# ECC_AGGR4_ECC_AGGR register map
Vendor: Texas Instruments
Registers are 32-bit, access not given, reset 0x0 unless marked. A register's access mark holds for its fields unless they carry their own. Offsets are as the file gives them; [hi:lo] are bit positions.

## ECC_AGGR4_ECC_AGGR (part 6 of 6)
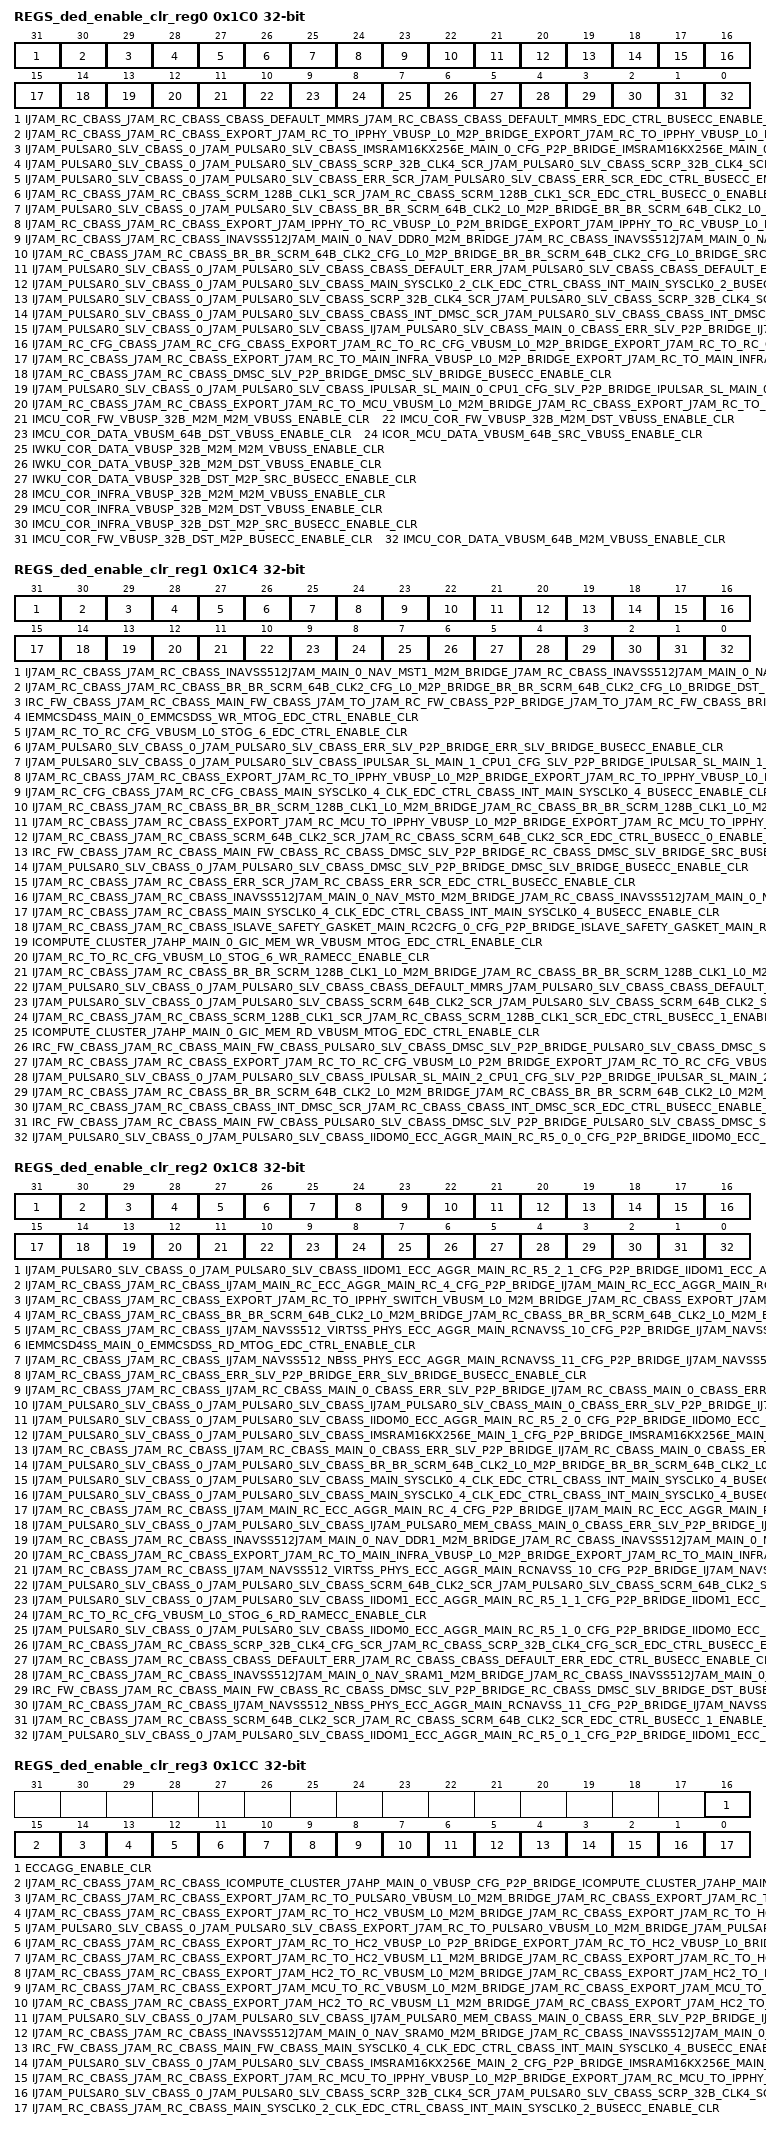
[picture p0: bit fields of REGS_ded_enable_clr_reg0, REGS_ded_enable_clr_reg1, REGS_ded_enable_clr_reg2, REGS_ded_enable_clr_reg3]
0x1C0 REGS_ded_enable_clr_reg0 — Interrupt Enable Clear Register 0
  [31] IJ7AM_RC_CBASS_J7AM_RC_CBASS_CBASS_DEFAULT_MMRS_J7AM_RC_CBASS_CBASS_DEFAULT_MMRS_EDC_CTRL_BUSECC_ENABLE_CLR — Interrupt Enable Clear Register for Ij7am_rc_cbass_j7am_rc_cbass_cbass_default_mmrs_j7am_rc_cbass_cbass_default_mmrs_edc_ctrl_busecc_pend (access R/W1TC)
  [30] IJ7AM_RC_CBASS_J7AM_RC_CBASS_EXPORT_J7AM_RC_TO_IPPHY_VBUSP_L0_M2P_BRIDGE_EXPORT_J7AM_RC_TO_IPPHY_VBUSP_L0_BRIDGE_DST_BUSECC_ENABLE_CLR — Interrupt Enable Clear Register for Ij7am_rc_cbass_j7am_rc_cbass_export_j7am_rc_to_ipphy_vbusp_l0_m2p_bridge_export_j7am_rc_to_ipphy_vbusp_l0_bridge_dst_busecc_pend (access R/W1TC)
  [29] IJ7AM_PULSAR0_SLV_CBASS_0_J7AM_PULSAR0_SLV_CBASS_IMSRAM16KX256E_MAIN_0_CFG_P2P_BRIDGE_IMSRAM16KX256E_MAIN_0_CFG_BRIDGE_BUSECC_ENABLE_CLR — Interrupt Enable Clear Register for Ij7am_pulsar0_slv_cbass_0_j7am_pulsar0_slv_cbass_Imsram16kx256e_main_0_cfg_p2p_bridge_Imsram16kx256e_main_0_cfg_bridge_busecc_pend (access R/W1TC)
  [28] IJ7AM_PULSAR0_SLV_CBASS_0_J7AM_PULSAR0_SLV_CBASS_SCRP_32B_CLK4_SCR_J7AM_PULSAR0_SLV_CBASS_SCRP_32B_CLK4_SCR_EDC_CTRL_BUSECC_2_ENABLE_CLR — Interrupt Enable Clear Register for Ij7am_pulsar0_slv_cbass_0_j7am_pulsar0_slv_cbass_scrp_32b_clk4_scr_j7am_pulsar0_slv_cbass_scrp_32b_clk4_scr_edc_ctrl_busecc_2_pend (access R/W1TC)
  [27] IJ7AM_PULSAR0_SLV_CBASS_0_J7AM_PULSAR0_SLV_CBASS_ERR_SCR_J7AM_PULSAR0_SLV_CBASS_ERR_SCR_EDC_CTRL_BUSECC_ENABLE_CLR — Interrupt Enable Clear Register for Ij7am_pulsar0_slv_cbass_0_j7am_pulsar0_slv_cbass_err_scr_j7am_pulsar0_slv_cbass_err_scr_edc_ctrl_busecc_pend (access R/W1TC)
  [26] IJ7AM_RC_CBASS_J7AM_RC_CBASS_SCRM_128B_CLK1_SCR_J7AM_RC_CBASS_SCRM_128B_CLK1_SCR_EDC_CTRL_BUSECC_0_ENABLE_CLR — Interrupt Enable Clear Register for Ij7am_rc_cbass_j7am_rc_cbass_scrm_128b_clk1_scr_j7am_rc_cbass_scrm_128b_clk1_scr_edc_ctrl_busecc_0_pend (access R/W1TC)
  [25] IJ7AM_PULSAR0_SLV_CBASS_0_J7AM_PULSAR0_SLV_CBASS_BR_BR_SCRM_64B_CLK2_L0_M2P_BRIDGE_BR_BR_SCRM_64B_CLK2_L0_BRIDGE_DST_BUSECC_ENABLE_CLR — Interrupt Enable Clear Register for Ij7am_pulsar0_slv_cbass_0_j7am_pulsar0_slv_cbass_br_br_scrm_64b_clk2_l0_m2p_bridge_br_br_scrm_64b_clk2_l0_bridge_dst_busecc_pend (access R/W1TC)
  [24] IJ7AM_RC_CBASS_J7AM_RC_CBASS_EXPORT_J7AM_IPPHY_TO_RC_VBUSP_L0_P2M_BRIDGE_EXPORT_J7AM_IPPHY_TO_RC_VBUSP_L0_BRIDGE_BUSECC_ENABLE_CLR — Interrupt Enable Clear Register for Ij7am_rc_cbass_j7am_rc_cbass_export_j7am_ipphy_to_rc_vbusp_l0_p2m_bridge_export_j7am_ipphy_to_rc_vbusp_l0_bridge_busecc_pend (access R/W1TC)
  [23] IJ7AM_RC_CBASS_J7AM_RC_CBASS_INAVSS512J7AM_MAIN_0_NAV_DDR0_M2M_BRIDGE_J7AM_RC_CBASS_INAVSS512J7AM_MAIN_0_NAV_DDR0_M2M_BRIDGE_SRC_EDC_CTRL_BUSECC_ENABLE_CLR — Interrupt Enable Clear Register for Ij7am_rc_cbass_j7am_rc_cbass_Inavss512j7am_main_0_nav_ddr0_m2m_bridge_j7am_rc_cbass_Inavss512j7am_main_0_nav_ddr0_m2m_bridge_src_edc_ctrl_busecc_pend (access R/W1TC)
  [22] IJ7AM_RC_CBASS_J7AM_RC_CBASS_BR_BR_SCRM_64B_CLK2_CFG_L0_M2P_BRIDGE_BR_BR_SCRM_64B_CLK2_CFG_L0_BRIDGE_SRC_BUSECC_ENABLE_CLR — Interrupt Enable Clear Register for Ij7am_rc_cbass_j7am_rc_cbass_br_br_scrm_64b_clk2_cfg_l0_m2p_bridge_br_br_scrm_64b_clk2_cfg_l0_bridge_src_busecc_pend (access R/W1TC)
  [21] IJ7AM_PULSAR0_SLV_CBASS_0_J7AM_PULSAR0_SLV_CBASS_CBASS_DEFAULT_ERR_J7AM_PULSAR0_SLV_CBASS_CBASS_DEFAULT_ERR_EDC_CTRL_BUSECC_ENABLE_CLR — Interrupt Enable Clear Register for Ij7am_pulsar0_slv_cbass_0_j7am_pulsar0_slv_cbass_cbass_default_err_j7am_pulsar0_slv_cbass_cbass_default_err_edc_ctrl_busecc_pend (access R/W1TC)
  [20] IJ7AM_PULSAR0_SLV_CBASS_0_J7AM_PULSAR0_SLV_CBASS_MAIN_SYSCLK0_2_CLK_EDC_CTRL_CBASS_INT_MAIN_SYSCLK0_2_BUSECC_ENABLE_CLR — Interrupt Enable Clear Register for Ij7am_pulsar0_slv_cbass_0_j7am_pulsar0_slv_cbass_main_SYSCLK0_2_clk_edc_ctrl_cbass_int_main_SYSCLK0_2_busecc_pend (access R/W1TC)
  [19] IJ7AM_PULSAR0_SLV_CBASS_0_J7AM_PULSAR0_SLV_CBASS_SCRP_32B_CLK4_SCR_J7AM_PULSAR0_SLV_CBASS_SCRP_32B_CLK4_SCR_EDC_CTRL_BUSECC_1_ENABLE_CLR — Interrupt Enable Clear Register for Ij7am_pulsar0_slv_cbass_0_j7am_pulsar0_slv_cbass_scrp_32b_clk4_scr_j7am_pulsar0_slv_cbass_scrp_32b_clk4_scr_edc_ctrl_busecc_1_pend (access R/W1TC)
  [18] IJ7AM_PULSAR0_SLV_CBASS_0_J7AM_PULSAR0_SLV_CBASS_CBASS_INT_DMSC_SCR_J7AM_PULSAR0_SLV_CBASS_CBASS_INT_DMSC_SCR_EDC_CTRL_BUSECC_ENABLE_CLR — Interrupt Enable Clear Register for Ij7am_pulsar0_slv_cbass_0_j7am_pulsar0_slv_cbass_cbass_int_dmsc_scr_j7am_pulsar0_slv_cbass_cbass_int_dmsc_scr_edc_ctrl_busecc_pend (access R/W1TC)
  [17] IJ7AM_PULSAR0_SLV_CBASS_0_J7AM_PULSAR0_SLV_CBASS_IJ7AM_PULSAR0_SLV_CBASS_MAIN_0_CBASS_ERR_SLV_P2P_BRIDGE_IJ7AM_PULSAR0_SLV_CBASS_MAIN_0_CBASS_ERR_SLV_BRIDGE_SRC_BUSECC_ENABLE_CLR — Interrupt Enable Clear Register for Ij7am_pulsar0_slv_cbass_0_j7am_pulsar0_slv_cbass_Ij7am_pulsar0_slv_cbass_main_0_cbass_err_slv_p2p_bridge_Ij7am_pulsar0_slv_cbass_main_0_cbass_err_slv_bridge_src_busecc_pend (access R/W1TC)
  [16] IJ7AM_RC_CFG_CBASS_J7AM_RC_CFG_CBASS_EXPORT_J7AM_RC_TO_RC_CFG_VBUSM_L0_M2P_BRIDGE_EXPORT_J7AM_RC_TO_RC_CFG_VBUSM_L0_BRIDGE_BUSECC_ENABLE_CLR — Interrupt Enable Clear Register for Ij7am_rc_cfg_cbass_j7am_rc_cfg_cbass_export_j7am_rc_to_rc_cfg_vbusm_l0_m2p_bridge_export_j7am_rc_to_rc_cfg_vbusm_l0_bridge_busecc_pend (access R/W1TC)
  [15] IJ7AM_RC_CBASS_J7AM_RC_CBASS_EXPORT_J7AM_RC_TO_MAIN_INFRA_VBUSP_L0_M2P_BRIDGE_EXPORT_J7AM_RC_TO_MAIN_INFRA_VBUSP_L0_BRIDGE_SRC_BUSECC_ENABLE_CLR — Interrupt Enable Clear Register for Ij7am_rc_cbass_j7am_rc_cbass_export_j7am_rc_to_main_infra_vbusp_l0_m2p_bridge_export_j7am_rc_to_main_infra_vbusp_l0_bridge_src_busecc_pend (access R/W1TC)
  [14] IJ7AM_RC_CBASS_J7AM_RC_CBASS_DMSC_SLV_P2P_BRIDGE_DMSC_SLV_BRIDGE_BUSECC_ENABLE_CLR — Interrupt Enable Clear Register for Ij7am_rc_cbass_j7am_rc_cbass_dmsc_slv_p2p_bridge_dmsc_slv_bridge_busecc_pend (access R/W1TC)
  [13] IJ7AM_PULSAR0_SLV_CBASS_0_J7AM_PULSAR0_SLV_CBASS_IPULSAR_SL_MAIN_0_CPU1_CFG_SLV_P2P_BRIDGE_IPULSAR_SL_MAIN_0_CPU1_CFG_SLV_BRIDGE_BUSECC_ENABLE_CLR — Interrupt Enable Clear Register for Ij7am_pulsar0_slv_cbass_0_j7am_pulsar0_slv_cbass_Ipulsar_sl_main_0_cpu1_cfg_slv_p2p_bridge_Ipulsar_sl_main_0_cpu1_cfg_slv_bridge_busecc_pend (access R/W1TC)
  [12] IJ7AM_RC_CBASS_J7AM_RC_CBASS_EXPORT_J7AM_RC_TO_MCU_VBUSM_L0_M2M_BRIDGE_J7AM_RC_CBASS_EXPORT_J7AM_RC_TO_MCU_VBUSM_L0_M2M_BRIDGE_SRC_EDC_CTRL_BUSECC_ENABLE_CLR — Interrupt Enable Clear Register for Ij7am_rc_cbass_j7am_rc_cbass_export_j7am_rc_to_mcu_vbusm_l0_m2m_bridge_j7am_rc_cbass_export_j7am_rc_to_mcu_vbusm_l0_m2m_bridge_src_edc_ctrl_busecc_pend (access R/W1TC)
  [11] IMCU_COR_FW_VBUSP_32B_M2M_M2M_VBUSS_ENABLE_CLR — Interrupt Enable Clear Register for Imcu_cor_fw_vbusp_32b_m2m_m2m_vbuss_pend (access R/W1TC)
  [10] IMCU_COR_FW_VBUSP_32B_M2M_DST_VBUSS_ENABLE_CLR — Interrupt Enable Clear Register for Imcu_cor_fw_vbusp_32b_m2m_dst_vbuss_pend (access R/W1TC)
  [9] IMCU_COR_DATA_VBUSM_64B_DST_VBUSS_ENABLE_CLR — Interrupt Enable Clear Register for Imcu_cor_data_vbusm_64b_dst_vbuss_pend (access R/W1TC)
  [8] ICOR_MCU_DATA_VBUSM_64B_SRC_VBUSS_ENABLE_CLR — Interrupt Enable Clear Register for Icor_mcu_data_vbusm_64b_src_vbuss_pend (access R/W1TC)
  [7] IWKU_COR_DATA_VBUSP_32B_M2M_M2M_VBUSS_ENABLE_CLR — Interrupt Enable Clear Register for Iwku_cor_data_vbusp_32b_m2m_m2m_vbuss_pend (access R/W1TC)
  [6] IWKU_COR_DATA_VBUSP_32B_M2M_DST_VBUSS_ENABLE_CLR — Interrupt Enable Clear Register for Iwku_cor_data_vbusp_32b_m2m_dst_vbuss_pend (access R/W1TC)
  [5] IWKU_COR_DATA_VBUSP_32B_DST_M2P_SRC_BUSECC_ENABLE_CLR — Interrupt Enable Clear Register for Iwku_cor_data_vbusp_32b_dst_m2p_src_busecc_pend (access R/W1TC)
  [4] IMCU_COR_INFRA_VBUSP_32B_M2M_M2M_VBUSS_ENABLE_CLR — Interrupt Enable Clear Register for Imcu_cor_infra_vbusp_32b_m2m_m2m_vbuss_pend (access R/W1TC)
  [3] IMCU_COR_INFRA_VBUSP_32B_M2M_DST_VBUSS_ENABLE_CLR — Interrupt Enable Clear Register for Imcu_cor_infra_vbusp_32b_m2m_dst_vbuss_pend (access R/W1TC)
  [2] IMCU_COR_INFRA_VBUSP_32B_DST_M2P_SRC_BUSECC_ENABLE_CLR — Interrupt Enable Clear Register for Imcu_cor_infra_vbusp_32b_dst_m2p_src_busecc_pend (access R/W1TC)
  [1] IMCU_COR_FW_VBUSP_32B_DST_M2P_BUSECC_ENABLE_CLR — Interrupt Enable Clear Register for Imcu_cor_fw_vbusp_32b_dst_m2p_busecc_pend (access R/W1TC)
  [0] IMCU_COR_DATA_VBUSM_64B_M2M_VBUSS_ENABLE_CLR — Interrupt Enable Clear Register for Imcu_cor_data_vbusm_64b_m2m_vbuss_pend (access R/W1TC)
0x1C4 REGS_ded_enable_clr_reg1 — Interrupt Enable Clear Register 1
  [31] IJ7AM_RC_CBASS_J7AM_RC_CBASS_INAVSS512J7AM_MAIN_0_NAV_MST1_M2M_BRIDGE_J7AM_RC_CBASS_INAVSS512J7AM_MAIN_0_NAV_MST1_M2M_BRIDGE_SRC_EDC_CTRL_BUSECC_ENABLE_CLR — Interrupt Enable Clear Register for Ij7am_rc_cbass_j7am_rc_cbass_Inavss512j7am_main_0_nav_mst1_m2m_bridge_j7am_rc_cbass_Inavss512j7am_main_0_nav_mst1_m2m_bridge_src_edc_ctrl_busecc_pend (access R/W1TC)
  [30] IJ7AM_RC_CBASS_J7AM_RC_CBASS_BR_BR_SCRM_64B_CLK2_CFG_L0_M2P_BRIDGE_BR_BR_SCRM_64B_CLK2_CFG_L0_BRIDGE_DST_BUSECC_ENABLE_CLR — Interrupt Enable Clear Register for Ij7am_rc_cbass_j7am_rc_cbass_br_br_scrm_64b_clk2_cfg_l0_m2p_bridge_br_br_scrm_64b_clk2_cfg_l0_bridge_dst_busecc_pend (access R/W1TC)
  [29] IRC_FW_CBASS_J7AM_RC_CBASS_MAIN_FW_CBASS_J7AM_TO_J7AM_RC_FW_CBASS_P2P_BRIDGE_J7AM_TO_J7AM_RC_FW_CBASS_BRIDGE_BUSECC_ENABLE_CLR — Interrupt Enable Clear Register for Irc_fw_cbass_j7am_rc_cbass_main_fw_cbass_j7am_to_j7am_rc_fw_cbass_p2p_bridge_j7am_to_j7am_rc_fw_cbass_bridge_busecc_pend (access R/W1TC)
  [28] IEMMCSD4SS_MAIN_0_EMMCSDSS_WR_MTOG_EDC_CTRL_ENABLE_CLR — Interrupt Enable Clear Register for Iemmcsd4ss_main_0_emmcsdss_wr_mtog_edc_ctrl_pend (access R/W1TC)
  [27] IJ7AM_RC_TO_RC_CFG_VBUSM_L0_STOG_6_EDC_CTRL_ENABLE_CLR — Interrupt Enable Clear Register for Ij7am_rc_to_rc_cfg_vbusm_l0_stog_6_edc_ctrl_pend (access R/W1TC)
  [26] IJ7AM_PULSAR0_SLV_CBASS_0_J7AM_PULSAR0_SLV_CBASS_ERR_SLV_P2P_BRIDGE_ERR_SLV_BRIDGE_BUSECC_ENABLE_CLR — Interrupt Enable Clear Register for Ij7am_pulsar0_slv_cbass_0_j7am_pulsar0_slv_cbass_err_slv_p2p_bridge_err_slv_bridge_busecc_pend (access R/W1TC)
  [25] IJ7AM_PULSAR0_SLV_CBASS_0_J7AM_PULSAR0_SLV_CBASS_IPULSAR_SL_MAIN_1_CPU1_CFG_SLV_P2P_BRIDGE_IPULSAR_SL_MAIN_1_CPU1_CFG_SLV_BRIDGE_BUSECC_ENABLE_CLR — Interrupt Enable Clear Register for Ij7am_pulsar0_slv_cbass_0_j7am_pulsar0_slv_cbass_Ipulsar_sl_main_1_cpu1_cfg_slv_p2p_bridge_Ipulsar_sl_main_1_cpu1_cfg_slv_bridge_busecc_pend (access R/W1TC)
  [24] IJ7AM_RC_CBASS_J7AM_RC_CBASS_EXPORT_J7AM_RC_TO_IPPHY_VBUSP_L0_M2P_BRIDGE_EXPORT_J7AM_RC_TO_IPPHY_VBUSP_L0_BRIDGE_SRC_BUSECC_ENABLE_CLR — Interrupt Enable Clear Register for Ij7am_rc_cbass_j7am_rc_cbass_export_j7am_rc_to_ipphy_vbusp_l0_m2p_bridge_export_j7am_rc_to_ipphy_vbusp_l0_bridge_src_busecc_pend (access R/W1TC)
  [23] IJ7AM_RC_CFG_CBASS_J7AM_RC_CFG_CBASS_MAIN_SYSCLK0_4_CLK_EDC_CTRL_CBASS_INT_MAIN_SYSCLK0_4_BUSECC_ENABLE_CLR — Interrupt Enable Clear Register for Ij7am_rc_cfg_cbass_j7am_rc_cfg_cbass_main_SYSCLK0_4_clk_edc_ctrl_cbass_int_main_SYSCLK0_4_busecc_pend (access R/W1TC)
  [22] IJ7AM_RC_CBASS_J7AM_RC_CBASS_BR_BR_SCRM_128B_CLK1_L0_M2M_BRIDGE_J7AM_RC_CBASS_BR_BR_SCRM_128B_CLK1_L0_M2M_BRIDGE_SRC_EDC_CTRL_BUSECC_ENABLE_CLR — Interrupt Enable Clear Register for Ij7am_rc_cbass_j7am_rc_cbass_br_br_scrm_128b_clk1_l0_m2m_bridge_j7am_rc_cbass_br_br_scrm_128b_clk1_l0_m2m_bridge_src_edc_ctrl_busecc_pend (access R/W1TC)
  [21] IJ7AM_RC_CBASS_J7AM_RC_CBASS_EXPORT_J7AM_RC_MCU_TO_IPPHY_VBUSP_L0_M2P_BRIDGE_EXPORT_J7AM_RC_MCU_TO_IPPHY_VBUSP_L0_BRIDGE_DST_BUSECC_ENABLE_CLR — Interrupt Enable Clear Register for Ij7am_rc_cbass_j7am_rc_cbass_export_j7am_rc_mcu_to_ipphy_vbusp_l0_m2p_bridge_export_j7am_rc_mcu_to_ipphy_vbusp_l0_bridge_dst_busecc_pend (access R/W1TC)
  [20] IJ7AM_RC_CBASS_J7AM_RC_CBASS_SCRM_64B_CLK2_SCR_J7AM_RC_CBASS_SCRM_64B_CLK2_SCR_EDC_CTRL_BUSECC_0_ENABLE_CLR — Interrupt Enable Clear Register for Ij7am_rc_cbass_j7am_rc_cbass_scrm_64b_clk2_scr_j7am_rc_cbass_scrm_64b_clk2_scr_edc_ctrl_busecc_0_pend (access R/W1TC)
  [19] IRC_FW_CBASS_J7AM_RC_CBASS_MAIN_FW_CBASS_RC_CBASS_DMSC_SLV_P2P_BRIDGE_RC_CBASS_DMSC_SLV_BRIDGE_SRC_BUSECC_ENABLE_CLR — Interrupt Enable Clear Register for Irc_fw_cbass_j7am_rc_cbass_main_fw_cbass_rc_cbass_dmsc_slv_p2p_bridge_rc_cbass_dmsc_slv_bridge_src_busecc_pend (access R/W1TC)
  [18] IJ7AM_PULSAR0_SLV_CBASS_0_J7AM_PULSAR0_SLV_CBASS_DMSC_SLV_P2P_BRIDGE_DMSC_SLV_BRIDGE_BUSECC_ENABLE_CLR — Interrupt Enable Clear Register for Ij7am_pulsar0_slv_cbass_0_j7am_pulsar0_slv_cbass_dmsc_slv_p2p_bridge_dmsc_slv_bridge_busecc_pend (access R/W1TC)
  [17] IJ7AM_RC_CBASS_J7AM_RC_CBASS_ERR_SCR_J7AM_RC_CBASS_ERR_SCR_EDC_CTRL_BUSECC_ENABLE_CLR — Interrupt Enable Clear Register for Ij7am_rc_cbass_j7am_rc_cbass_err_scr_j7am_rc_cbass_err_scr_edc_ctrl_busecc_pend (access R/W1TC)
  [16] IJ7AM_RC_CBASS_J7AM_RC_CBASS_INAVSS512J7AM_MAIN_0_NAV_MST0_M2M_BRIDGE_J7AM_RC_CBASS_INAVSS512J7AM_MAIN_0_NAV_MST0_M2M_BRIDGE_SRC_EDC_CTRL_BUSECC_ENABLE_CLR — Interrupt Enable Clear Register for Ij7am_rc_cbass_j7am_rc_cbass_Inavss512j7am_main_0_nav_mst0_m2m_bridge_j7am_rc_cbass_Inavss512j7am_main_0_nav_mst0_m2m_bridge_src_edc_ctrl_busecc_pend (access R/W1TC)
  [15] IJ7AM_RC_CBASS_J7AM_RC_CBASS_MAIN_SYSCLK0_4_CLK_EDC_CTRL_CBASS_INT_MAIN_SYSCLK0_4_BUSECC_ENABLE_CLR — Interrupt Enable Clear Register for Ij7am_rc_cbass_j7am_rc_cbass_main_SYSCLK0_4_clk_edc_ctrl_cbass_int_main_SYSCLK0_4_busecc_pend (access R/W1TC)
  [14] IJ7AM_RC_CBASS_J7AM_RC_CBASS_ISLAVE_SAFETY_GASKET_MAIN_RC2CFG_0_CFG_P2P_BRIDGE_ISLAVE_SAFETY_GASKET_MAIN_RC2CFG_0_CFG_BRIDGE_BUSECC_ENABLE_CLR — Interrupt Enable Clear Register for Ij7am_rc_cbass_j7am_rc_cbass_Islave_safety_gasket_main_rc2cfg_0_cfg_p2p_bridge_Islave_safety_gasket_main_rc2cfg_0_cfg_bridge_busecc_pend (access R/W1TC)
  [13] ICOMPUTE_CLUSTER_J7AHP_MAIN_0_GIC_MEM_WR_VBUSM_MTOG_EDC_CTRL_ENABLE_CLR — Interrupt Enable Clear Register for Icompute_cluster_j7ahp_main_0_gic_mem_wr_vbusm_mtog_edc_ctrl_pend (access R/W1TC)
  [12] IJ7AM_RC_TO_RC_CFG_VBUSM_L0_STOG_6_WR_RAMECC_ENABLE_CLR — Interrupt Enable Clear Register for Ij7am_rc_to_rc_cfg_vbusm_l0_stog_6_wr_ramecc_pend (access R/W1TC)
  [11] IJ7AM_RC_CBASS_J7AM_RC_CBASS_BR_BR_SCRM_128B_CLK1_L0_M2M_BRIDGE_J7AM_RC_CBASS_BR_BR_SCRM_128B_CLK1_L0_M2M_BRIDGE_DST_EDC_CTRL_BUSECC_ENABLE_CLR — Interrupt Enable Clear Register for Ij7am_rc_cbass_j7am_rc_cbass_br_br_scrm_128b_clk1_l0_m2m_bridge_j7am_rc_cbass_br_br_scrm_128b_clk1_l0_m2m_bridge_dst_edc_ctrl_busecc_pend (access R/W1TC)
  [10] IJ7AM_PULSAR0_SLV_CBASS_0_J7AM_PULSAR0_SLV_CBASS_CBASS_DEFAULT_MMRS_J7AM_PULSAR0_SLV_CBASS_CBASS_DEFAULT_MMRS_EDC_CTRL_BUSECC_ENABLE_CLR — Interrupt Enable Clear Register for Ij7am_pulsar0_slv_cbass_0_j7am_pulsar0_slv_cbass_cbass_default_mmrs_j7am_pulsar0_slv_cbass_cbass_default_mmrs_edc_ctrl_busecc_pend (access R/W1TC)
  [9] IJ7AM_PULSAR0_SLV_CBASS_0_J7AM_PULSAR0_SLV_CBASS_SCRM_64B_CLK2_SCR_J7AM_PULSAR0_SLV_CBASS_SCRM_64B_CLK2_SCR_EDC_CTRL_BUSECC_1_ENABLE_CLR — Interrupt Enable Clear Register for Ij7am_pulsar0_slv_cbass_0_j7am_pulsar0_slv_cbass_scrm_64b_clk2_scr_j7am_pulsar0_slv_cbass_scrm_64b_clk2_scr_edc_ctrl_busecc_1_pend (access R/W1TC)
  [8] IJ7AM_RC_CBASS_J7AM_RC_CBASS_SCRM_128B_CLK1_SCR_J7AM_RC_CBASS_SCRM_128B_CLK1_SCR_EDC_CTRL_BUSECC_1_ENABLE_CLR — Interrupt Enable Clear Register for Ij7am_rc_cbass_j7am_rc_cbass_scrm_128b_clk1_scr_j7am_rc_cbass_scrm_128b_clk1_scr_edc_ctrl_busecc_1_pend (access R/W1TC)
  [7] ICOMPUTE_CLUSTER_J7AHP_MAIN_0_GIC_MEM_RD_VBUSM_MTOG_EDC_CTRL_ENABLE_CLR — Interrupt Enable Clear Register for Icompute_cluster_j7ahp_main_0_gic_mem_rd_vbusm_mtog_edc_ctrl_pend (access R/W1TC)
  [6] IRC_FW_CBASS_J7AM_RC_CBASS_MAIN_FW_CBASS_PULSAR0_SLV_CBASS_DMSC_SLV_P2P_BRIDGE_PULSAR0_SLV_CBASS_DMSC_SLV_BRIDGE_DST_BUSECC_ENABLE_CLR — Interrupt Enable Clear Register for Irc_fw_cbass_j7am_rc_cbass_main_fw_cbass_pulsar0_slv_cbass_dmsc_slv_p2p_bridge_pulsar0_slv_cbass_dmsc_slv_bridge_dst_busecc_pend (access R/W1TC)
  [5] IJ7AM_RC_CBASS_J7AM_RC_CBASS_EXPORT_J7AM_RC_TO_RC_CFG_VBUSM_L0_P2M_BRIDGE_EXPORT_J7AM_RC_TO_RC_CFG_VBUSM_L0_BRIDGE_BUSECC_ENABLE_CLR — Interrupt Enable Clear Register for Ij7am_rc_cbass_j7am_rc_cbass_export_j7am_rc_to_rc_cfg_vbusm_l0_p2m_bridge_export_j7am_rc_to_rc_cfg_vbusm_l0_bridge_busecc_pend (access R/W1TC)
  [4] IJ7AM_PULSAR0_SLV_CBASS_0_J7AM_PULSAR0_SLV_CBASS_IPULSAR_SL_MAIN_2_CPU1_CFG_SLV_P2P_BRIDGE_IPULSAR_SL_MAIN_2_CPU1_CFG_SLV_BRIDGE_BUSECC_ENABLE_CLR — Interrupt Enable Clear Register for Ij7am_pulsar0_slv_cbass_0_j7am_pulsar0_slv_cbass_Ipulsar_sl_main_2_cpu1_cfg_slv_p2p_bridge_Ipulsar_sl_main_2_cpu1_cfg_slv_bridge_busecc_pend (access R/W1TC)
  [3] IJ7AM_RC_CBASS_J7AM_RC_CBASS_BR_BR_SCRM_64B_CLK2_L0_M2M_BRIDGE_J7AM_RC_CBASS_BR_BR_SCRM_64B_CLK2_L0_M2M_BRIDGE_DST_EDC_CTRL_BUSECC_ENABLE_CLR — Interrupt Enable Clear Register for Ij7am_rc_cbass_j7am_rc_cbass_br_br_scrm_64b_clk2_l0_m2m_bridge_j7am_rc_cbass_br_br_scrm_64b_clk2_l0_m2m_bridge_dst_edc_ctrl_busecc_pend (access R/W1TC)
  [2] IJ7AM_RC_CBASS_J7AM_RC_CBASS_CBASS_INT_DMSC_SCR_J7AM_RC_CBASS_CBASS_INT_DMSC_SCR_EDC_CTRL_BUSECC_ENABLE_CLR — Interrupt Enable Clear Register for Ij7am_rc_cbass_j7am_rc_cbass_cbass_int_dmsc_scr_j7am_rc_cbass_cbass_int_dmsc_scr_edc_ctrl_busecc_pend (access R/W1TC)
  [1] IRC_FW_CBASS_J7AM_RC_CBASS_MAIN_FW_CBASS_PULSAR0_SLV_CBASS_DMSC_SLV_P2P_BRIDGE_PULSAR0_SLV_CBASS_DMSC_SLV_BRIDGE_SRC_BUSECC_ENABLE_CLR — Interrupt Enable Clear Register for Irc_fw_cbass_j7am_rc_cbass_main_fw_cbass_pulsar0_slv_cbass_dmsc_slv_p2p_bridge_pulsar0_slv_cbass_dmsc_slv_bridge_src_busecc_pend (access R/W1TC)
  [0] IJ7AM_PULSAR0_SLV_CBASS_0_J7AM_PULSAR0_SLV_CBASS_IIDOM0_ECC_AGGR_MAIN_RC_R5_0_0_CFG_P2P_BRIDGE_IIDOM0_ECC_AGGR_MAIN_RC_R5_0_0_CFG_BRIDGE_BUSECC_ENABLE_CLR — Interrupt Enable Clear Register for Ij7am_pulsar0_slv_cbass_0_j7am_pulsar0_slv_cbass_IIdom0_ecc_aggr_main_rc_r5_0_0_cfg_p2p_bridge_IIdom0_ecc_aggr_main_rc_r5_0_0_cfg_bridge_busecc_pend (access R/W1TC)
0x1C8 REGS_ded_enable_clr_reg2 — Interrupt Enable Clear Register 2
  [31] IJ7AM_PULSAR0_SLV_CBASS_0_J7AM_PULSAR0_SLV_CBASS_IIDOM1_ECC_AGGR_MAIN_RC_R5_2_1_CFG_P2P_BRIDGE_IIDOM1_ECC_AGGR_MAIN_RC_R5_2_1_CFG_BRIDGE_BUSECC_ENABLE_CLR — Interrupt Enable Clear Register for Ij7am_pulsar0_slv_cbass_0_j7am_pulsar0_slv_cbass_IIdom1_ecc_aggr_main_rc_r5_2_1_cfg_p2p_bridge_IIdom1_ecc_aggr_main_rc_r5_2_1_cfg_bridge_busecc_pend (access R/W1TC)
  [30] IJ7AM_RC_CBASS_J7AM_RC_CBASS_IJ7AM_MAIN_RC_ECC_AGGR_MAIN_RC_4_CFG_P2P_BRIDGE_IJ7AM_MAIN_RC_ECC_AGGR_MAIN_RC_4_CFG_BRIDGE_SRC_BUSECC_ENABLE_CLR — Interrupt Enable Clear Register for Ij7am_rc_cbass_j7am_rc_cbass_Ij7am_main_rc_ecc_aggr_main_rc_4_cfg_p2p_bridge_Ij7am_main_rc_ecc_aggr_main_rc_4_cfg_bridge_src_busecc_pend (access R/W1TC)
  [29] IJ7AM_RC_CBASS_J7AM_RC_CBASS_EXPORT_J7AM_RC_TO_IPPHY_SWITCH_VBUSM_L0_M2M_BRIDGE_J7AM_RC_CBASS_EXPORT_J7AM_RC_TO_IPPHY_SWITCH_VBUSM_L0_M2M_BRIDGE_SRC_EDC_CTRL_BUSECC_ENABLE_CLR — Interrupt Enable Clear Register for Ij7am_rc_cbass_j7am_rc_cbass_export_j7am_rc_to_ipphy_switch_vbusm_l0_m2m_bridge_j7am_rc_cbass_export_j7am_rc_to_ipphy_switch_vbusm_l0_m2m_bridge_src_edc_ctrl_busecc_pend (access R/W1TC)
  [28] IJ7AM_RC_CBASS_J7AM_RC_CBASS_BR_BR_SCRM_64B_CLK2_L0_M2M_BRIDGE_J7AM_RC_CBASS_BR_BR_SCRM_64B_CLK2_L0_M2M_BRIDGE_SRC_EDC_CTRL_BUSECC_ENABLE_CLR — Interrupt Enable Clear Register for Ij7am_rc_cbass_j7am_rc_cbass_br_br_scrm_64b_clk2_l0_m2m_bridge_j7am_rc_cbass_br_br_scrm_64b_clk2_l0_m2m_bridge_src_edc_ctrl_busecc_pend (access R/W1TC)
  [27] IJ7AM_RC_CBASS_J7AM_RC_CBASS_IJ7AM_NAVSS512_VIRTSS_PHYS_ECC_AGGR_MAIN_RCNAVSS_10_CFG_P2P_BRIDGE_IJ7AM_NAVSS512_VIRTSS_PHYS_ECC_AGGR_MAIN_RCNAVSS_10_CFG_BRIDGE_SRC_BUSECC_ENABLE_CLR — Interrupt Enable Clear Register for Ij7am_rc_cbass_j7am_rc_cbass_Ij7am_navss512_virtss_phys_ecc_aggr_main_rcnavss_10_cfg_p2p_bridge_Ij7am_navss512_virtss_phys_ecc_aggr_main_rcnavss_10_cfg_bridge_src_busecc_pend (access R/W1TC)
  [26] IEMMCSD4SS_MAIN_0_EMMCSDSS_RD_MTOG_EDC_CTRL_ENABLE_CLR — Interrupt Enable Clear Register for Iemmcsd4ss_main_0_emmcsdss_rd_mtog_edc_ctrl_pend (access R/W1TC)
  [25] IJ7AM_RC_CBASS_J7AM_RC_CBASS_IJ7AM_NAVSS512_NBSS_PHYS_ECC_AGGR_MAIN_RCNAVSS_11_CFG_P2P_BRIDGE_IJ7AM_NAVSS512_NBSS_PHYS_ECC_AGGR_MAIN_RCNAVSS_11_CFG_BRIDGE_DST_BUSECC_ENABLE_CLR — Interrupt Enable Clear Register for Ij7am_rc_cbass_j7am_rc_cbass_Ij7am_navss512_nbss_phys_ecc_aggr_main_rcnavss_11_cfg_p2p_bridge_Ij7am_navss512_nbss_phys_ecc_aggr_main_rcnavss_11_cfg_bridge_dst_busecc_pend (access R/W1TC)
  [24] IJ7AM_RC_CBASS_J7AM_RC_CBASS_ERR_SLV_P2P_BRIDGE_ERR_SLV_BRIDGE_BUSECC_ENABLE_CLR — Interrupt Enable Clear Register for Ij7am_rc_cbass_j7am_rc_cbass_err_slv_p2p_bridge_err_slv_bridge_busecc_pend (access R/W1TC)
  [23] IJ7AM_RC_CBASS_J7AM_RC_CBASS_IJ7AM_RC_CBASS_MAIN_0_CBASS_ERR_SLV_P2P_BRIDGE_IJ7AM_RC_CBASS_MAIN_0_CBASS_ERR_SLV_BRIDGE_SRC_BUSECC_ENABLE_CLR — Interrupt Enable Clear Register for Ij7am_rc_cbass_j7am_rc_cbass_Ij7am_rc_cbass_main_0_cbass_err_slv_p2p_bridge_Ij7am_rc_cbass_main_0_cbass_err_slv_bridge_src_busecc_pend (access R/W1TC)
  [22] IJ7AM_PULSAR0_SLV_CBASS_0_J7AM_PULSAR0_SLV_CBASS_IJ7AM_PULSAR0_SLV_CBASS_MAIN_0_CBASS_ERR_SLV_P2P_BRIDGE_IJ7AM_PULSAR0_SLV_CBASS_MAIN_0_CBASS_ERR_SLV_BRIDGE_DST_BUSECC_ENABLE_CLR — Interrupt Enable Clear Register for Ij7am_pulsar0_slv_cbass_0_j7am_pulsar0_slv_cbass_Ij7am_pulsar0_slv_cbass_main_0_cbass_err_slv_p2p_bridge_Ij7am_pulsar0_slv_cbass_main_0_cbass_err_slv_bridge_dst_busecc_pend (access R/W1TC)
  [21] IJ7AM_PULSAR0_SLV_CBASS_0_J7AM_PULSAR0_SLV_CBASS_IIDOM0_ECC_AGGR_MAIN_RC_R5_2_0_CFG_P2P_BRIDGE_IIDOM0_ECC_AGGR_MAIN_RC_R5_2_0_CFG_BRIDGE_BUSECC_ENABLE_CLR — Interrupt Enable Clear Register for Ij7am_pulsar0_slv_cbass_0_j7am_pulsar0_slv_cbass_IIdom0_ecc_aggr_main_rc_r5_2_0_cfg_p2p_bridge_IIdom0_ecc_aggr_main_rc_r5_2_0_cfg_bridge_busecc_pend (access R/W1TC)
  [20] IJ7AM_PULSAR0_SLV_CBASS_0_J7AM_PULSAR0_SLV_CBASS_IMSRAM16KX256E_MAIN_1_CFG_P2P_BRIDGE_IMSRAM16KX256E_MAIN_1_CFG_BRIDGE_BUSECC_ENABLE_CLR — Interrupt Enable Clear Register for Ij7am_pulsar0_slv_cbass_0_j7am_pulsar0_slv_cbass_Imsram16kx256e_main_1_cfg_p2p_bridge_Imsram16kx256e_main_1_cfg_bridge_busecc_pend (access R/W1TC)
  [19] IJ7AM_RC_CBASS_J7AM_RC_CBASS_IJ7AM_RC_CBASS_MAIN_0_CBASS_ERR_SLV_P2P_BRIDGE_IJ7AM_RC_CBASS_MAIN_0_CBASS_ERR_SLV_BRIDGE_DST_BUSECC_ENABLE_CLR — Interrupt Enable Clear Register for Ij7am_rc_cbass_j7am_rc_cbass_Ij7am_rc_cbass_main_0_cbass_err_slv_p2p_bridge_Ij7am_rc_cbass_main_0_cbass_err_slv_bridge_dst_busecc_pend (access R/W1TC)
  [18] IJ7AM_PULSAR0_SLV_CBASS_0_J7AM_PULSAR0_SLV_CBASS_BR_BR_SCRM_64B_CLK2_L0_M2P_BRIDGE_BR_BR_SCRM_64B_CLK2_L0_BRIDGE_SRC_BUSECC_ENABLE_CLR — Interrupt Enable Clear Register for Ij7am_pulsar0_slv_cbass_0_j7am_pulsar0_slv_cbass_br_br_scrm_64b_clk2_l0_m2p_bridge_br_br_scrm_64b_clk2_l0_bridge_src_busecc_pend (access R/W1TC)
  [17] IJ7AM_PULSAR0_SLV_CBASS_0_J7AM_PULSAR0_SLV_CBASS_MAIN_SYSCLK0_4_CLK_EDC_CTRL_CBASS_INT_MAIN_SYSCLK0_4_BUSECC_1_ENABLE_CLR — Interrupt Enable Clear Register for Ij7am_pulsar0_slv_cbass_0_j7am_pulsar0_slv_cbass_main_SYSCLK0_4_clk_edc_ctrl_cbass_int_main_SYSCLK0_4_busecc_1_pend (access R/W1TC)
  [16] IJ7AM_PULSAR0_SLV_CBASS_0_J7AM_PULSAR0_SLV_CBASS_MAIN_SYSCLK0_4_CLK_EDC_CTRL_CBASS_INT_MAIN_SYSCLK0_4_BUSECC_0_ENABLE_CLR — Interrupt Enable Clear Register for Ij7am_pulsar0_slv_cbass_0_j7am_pulsar0_slv_cbass_main_SYSCLK0_4_clk_edc_ctrl_cbass_int_main_SYSCLK0_4_busecc_0_pend (access R/W1TC)
  [15] IJ7AM_RC_CBASS_J7AM_RC_CBASS_IJ7AM_MAIN_RC_ECC_AGGR_MAIN_RC_4_CFG_P2P_BRIDGE_IJ7AM_MAIN_RC_ECC_AGGR_MAIN_RC_4_CFG_BRIDGE_DST_BUSECC_ENABLE_CLR — Interrupt Enable Clear Register for Ij7am_rc_cbass_j7am_rc_cbass_Ij7am_main_rc_ecc_aggr_main_rc_4_cfg_p2p_bridge_Ij7am_main_rc_ecc_aggr_main_rc_4_cfg_bridge_dst_busecc_pend (access R/W1TC)
  [14] IJ7AM_PULSAR0_SLV_CBASS_0_J7AM_PULSAR0_SLV_CBASS_IJ7AM_PULSAR0_MEM_CBASS_MAIN_0_CBASS_ERR_SLV_P2P_BRIDGE_IJ7AM_PULSAR0_MEM_CBASS_MAIN_0_CBASS_ERR_SLV_BRIDGE_SRC_BUSECC_ENABLE_CLR — Interrupt Enable Clear Register for Ij7am_pulsar0_slv_cbass_0_j7am_pulsar0_slv_cbass_Ij7am_pulsar0_mem_cbass_main_0_cbass_err_slv_p2p_bridge_Ij7am_pulsar0_mem_cbass_main_0_cbass_err_slv_bridge_src_busecc_pend (access R/W1TC)
  [13] IJ7AM_RC_CBASS_J7AM_RC_CBASS_INAVSS512J7AM_MAIN_0_NAV_DDR1_M2M_BRIDGE_J7AM_RC_CBASS_INAVSS512J7AM_MAIN_0_NAV_DDR1_M2M_BRIDGE_SRC_EDC_CTRL_BUSECC_ENABLE_CLR — Interrupt Enable Clear Register for Ij7am_rc_cbass_j7am_rc_cbass_Inavss512j7am_main_0_nav_ddr1_m2m_bridge_j7am_rc_cbass_Inavss512j7am_main_0_nav_ddr1_m2m_bridge_src_edc_ctrl_busecc_pend (access R/W1TC)
  [12] IJ7AM_RC_CBASS_J7AM_RC_CBASS_EXPORT_J7AM_RC_TO_MAIN_INFRA_VBUSP_L0_M2P_BRIDGE_EXPORT_J7AM_RC_TO_MAIN_INFRA_VBUSP_L0_BRIDGE_DST_BUSECC_ENABLE_CLR — Interrupt Enable Clear Register for Ij7am_rc_cbass_j7am_rc_cbass_export_j7am_rc_to_main_infra_vbusp_l0_m2p_bridge_export_j7am_rc_to_main_infra_vbusp_l0_bridge_dst_busecc_pend (access R/W1TC)
  [11] IJ7AM_RC_CBASS_J7AM_RC_CBASS_IJ7AM_NAVSS512_VIRTSS_PHYS_ECC_AGGR_MAIN_RCNAVSS_10_CFG_P2P_BRIDGE_IJ7AM_NAVSS512_VIRTSS_PHYS_ECC_AGGR_MAIN_RCNAVSS_10_CFG_BRIDGE_DST_BUSECC_ENABLE_CLR — Interrupt Enable Clear Register for Ij7am_rc_cbass_j7am_rc_cbass_Ij7am_navss512_virtss_phys_ecc_aggr_main_rcnavss_10_cfg_p2p_bridge_Ij7am_navss512_virtss_phys_ecc_aggr_main_rcnavss_10_cfg_bridge_dst_busecc_pend (access R/W1TC)
  [10] IJ7AM_PULSAR0_SLV_CBASS_0_J7AM_PULSAR0_SLV_CBASS_SCRM_64B_CLK2_SCR_J7AM_PULSAR0_SLV_CBASS_SCRM_64B_CLK2_SCR_EDC_CTRL_BUSECC_0_ENABLE_CLR — Interrupt Enable Clear Register for Ij7am_pulsar0_slv_cbass_0_j7am_pulsar0_slv_cbass_scrm_64b_clk2_scr_j7am_pulsar0_slv_cbass_scrm_64b_clk2_scr_edc_ctrl_busecc_0_pend (access R/W1TC)
  [9] IJ7AM_PULSAR0_SLV_CBASS_0_J7AM_PULSAR0_SLV_CBASS_IIDOM1_ECC_AGGR_MAIN_RC_R5_1_1_CFG_P2P_BRIDGE_IIDOM1_ECC_AGGR_MAIN_RC_R5_1_1_CFG_BRIDGE_BUSECC_ENABLE_CLR — Interrupt Enable Clear Register for Ij7am_pulsar0_slv_cbass_0_j7am_pulsar0_slv_cbass_IIdom1_ecc_aggr_main_rc_r5_1_1_cfg_p2p_bridge_IIdom1_ecc_aggr_main_rc_r5_1_1_cfg_bridge_busecc_pend (access R/W1TC)
  [8] IJ7AM_RC_TO_RC_CFG_VBUSM_L0_STOG_6_RD_RAMECC_ENABLE_CLR — Interrupt Enable Clear Register for Ij7am_rc_to_rc_cfg_vbusm_l0_stog_6_rd_ramecc_pend (access R/W1TC)
  [7] IJ7AM_PULSAR0_SLV_CBASS_0_J7AM_PULSAR0_SLV_CBASS_IIDOM0_ECC_AGGR_MAIN_RC_R5_1_0_CFG_P2P_BRIDGE_IIDOM0_ECC_AGGR_MAIN_RC_R5_1_0_CFG_BRIDGE_BUSECC_ENABLE_CLR — Interrupt Enable Clear Register for Ij7am_pulsar0_slv_cbass_0_j7am_pulsar0_slv_cbass_IIdom0_ecc_aggr_main_rc_r5_1_0_cfg_p2p_bridge_IIdom0_ecc_aggr_main_rc_r5_1_0_cfg_bridge_busecc_pend (access R/W1TC)
  [6] IJ7AM_RC_CBASS_J7AM_RC_CBASS_SCRP_32B_CLK4_CFG_SCR_J7AM_RC_CBASS_SCRP_32B_CLK4_CFG_SCR_EDC_CTRL_BUSECC_ENABLE_CLR — Interrupt Enable Clear Register for Ij7am_rc_cbass_j7am_rc_cbass_scrp_32b_clk4_cfg_scr_j7am_rc_cbass_scrp_32b_clk4_cfg_scr_edc_ctrl_busecc_pend (access R/W1TC)
  [5] IJ7AM_RC_CBASS_J7AM_RC_CBASS_CBASS_DEFAULT_ERR_J7AM_RC_CBASS_CBASS_DEFAULT_ERR_EDC_CTRL_BUSECC_ENABLE_CLR — Interrupt Enable Clear Register for Ij7am_rc_cbass_j7am_rc_cbass_cbass_default_err_j7am_rc_cbass_cbass_default_err_edc_ctrl_busecc_pend (access R/W1TC)
  [4] IJ7AM_RC_CBASS_J7AM_RC_CBASS_INAVSS512J7AM_MAIN_0_NAV_SRAM1_M2M_BRIDGE_J7AM_RC_CBASS_INAVSS512J7AM_MAIN_0_NAV_SRAM1_M2M_BRIDGE_SRC_EDC_CTRL_BUSECC_ENABLE_CLR — Interrupt Enable Clear Register for Ij7am_rc_cbass_j7am_rc_cbass_Inavss512j7am_main_0_nav_sram1_m2m_bridge_j7am_rc_cbass_Inavss512j7am_main_0_nav_sram1_m2m_bridge_src_edc_ctrl_busecc_pend (access R/W1TC)
  [3] IRC_FW_CBASS_J7AM_RC_CBASS_MAIN_FW_CBASS_RC_CBASS_DMSC_SLV_P2P_BRIDGE_RC_CBASS_DMSC_SLV_BRIDGE_DST_BUSECC_ENABLE_CLR — Interrupt Enable Clear Register for Irc_fw_cbass_j7am_rc_cbass_main_fw_cbass_rc_cbass_dmsc_slv_p2p_bridge_rc_cbass_dmsc_slv_bridge_dst_busecc_pend (access R/W1TC)
  [2] IJ7AM_RC_CBASS_J7AM_RC_CBASS_IJ7AM_NAVSS512_NBSS_PHYS_ECC_AGGR_MAIN_RCNAVSS_11_CFG_P2P_BRIDGE_IJ7AM_NAVSS512_NBSS_PHYS_ECC_AGGR_MAIN_RCNAVSS_11_CFG_BRIDGE_SRC_BUSECC_ENABLE_CLR — Interrupt Enable Clear Register for Ij7am_rc_cbass_j7am_rc_cbass_Ij7am_navss512_nbss_phys_ecc_aggr_main_rcnavss_11_cfg_p2p_bridge_Ij7am_navss512_nbss_phys_ecc_aggr_main_rcnavss_11_cfg_bridge_src_busecc_pend (access R/W1TC)
  [1] IJ7AM_RC_CBASS_J7AM_RC_CBASS_SCRM_64B_CLK2_SCR_J7AM_RC_CBASS_SCRM_64B_CLK2_SCR_EDC_CTRL_BUSECC_1_ENABLE_CLR — Interrupt Enable Clear Register for Ij7am_rc_cbass_j7am_rc_cbass_scrm_64b_clk2_scr_j7am_rc_cbass_scrm_64b_clk2_scr_edc_ctrl_busecc_1_pend (access R/W1TC)
  [0] IJ7AM_PULSAR0_SLV_CBASS_0_J7AM_PULSAR0_SLV_CBASS_IIDOM1_ECC_AGGR_MAIN_RC_R5_0_1_CFG_P2P_BRIDGE_IIDOM1_ECC_AGGR_MAIN_RC_R5_0_1_CFG_BRIDGE_BUSECC_ENABLE_CLR — Interrupt Enable Clear Register for Ij7am_pulsar0_slv_cbass_0_j7am_pulsar0_slv_cbass_IIdom1_ecc_aggr_main_rc_r5_0_1_cfg_p2p_bridge_IIdom1_ecc_aggr_main_rc_r5_0_1_cfg_bridge_busecc_pend (access R/W1TC)
0x1CC REGS_ded_enable_clr_reg3 — Interrupt Enable Clear Register 3
  [16] ECCAGG_ENABLE_CLR — Interrupt Enable Clear Register for eccagg_pend (access R/W1TC)
  [15] IJ7AM_RC_CBASS_J7AM_RC_CBASS_ICOMPUTE_CLUSTER_J7AHP_MAIN_0_VBUSP_CFG_P2P_BRIDGE_ICOMPUTE_CLUSTER_J7AHP_MAIN_0_VBUSP_CFG_BRIDGE_BUSECC_ENABLE_CLR — Interrupt Enable Clear Register for Ij7am_rc_cbass_j7am_rc_cbass_Icompute_cluster_j7ahp_main_0_vbusp_cfg_p2p_bridge_Icompute_cluster_j7ahp_main_0_vbusp_cfg_bridge_busecc_pend (access R/W1TC)
  [14] IJ7AM_RC_CBASS_J7AM_RC_CBASS_EXPORT_J7AM_RC_TO_PULSAR0_VBUSM_L0_M2M_BRIDGE_J7AM_RC_CBASS_EXPORT_J7AM_RC_TO_PULSAR0_VBUSM_L0_M2M_BRIDGE_SRC_EDC_CTRL_BUSECC_ENABLE_CLR — Interrupt Enable Clear Register for Ij7am_rc_cbass_j7am_rc_cbass_export_j7am_rc_to_pulsar0_vbusm_l0_m2m_bridge_j7am_rc_cbass_export_j7am_rc_to_pulsar0_vbusm_l0_m2m_bridge_src_edc_ctrl_busecc_pend (access R/W1TC)
  [13] IJ7AM_RC_CBASS_J7AM_RC_CBASS_EXPORT_J7AM_RC_TO_HC2_VBUSM_L0_M2M_BRIDGE_J7AM_RC_CBASS_EXPORT_J7AM_RC_TO_HC2_VBUSM_L0_M2M_BRIDGE_SRC_EDC_CTRL_BUSECC_ENABLE_CLR — Interrupt Enable Clear Register for Ij7am_rc_cbass_j7am_rc_cbass_export_j7am_rc_to_hc2_vbusm_l0_m2m_bridge_j7am_rc_cbass_export_j7am_rc_to_hc2_vbusm_l0_m2m_bridge_src_edc_ctrl_busecc_pend (access R/W1TC)
  [12] IJ7AM_PULSAR0_SLV_CBASS_0_J7AM_PULSAR0_SLV_CBASS_EXPORT_J7AM_RC_TO_PULSAR0_VBUSM_L0_M2M_BRIDGE_J7AM_PULSAR0_SLV_CBASS_EXPORT_J7AM_RC_TO_PULSAR0_VBUSM_L0_M2M_BRIDGE_SRC_EDC_CTRL_BUSECC_ENABLE_CLR — Interrupt Enable Clear Register for Ij7am_pulsar0_slv_cbass_0_j7am_pulsar0_slv_cbass_export_j7am_rc_to_pulsar0_vbusm_l0_m2m_bridge_j7am_pulsar0_slv_cbass_export_j7am_rc_to_pulsar0_vbusm_l0_m2m_bridge_src_edc_ctrl_busecc_pend (access R/W1TC)
  [11] IJ7AM_RC_CBASS_J7AM_RC_CBASS_EXPORT_J7AM_RC_TO_HC2_VBUSP_L0_P2P_BRIDGE_EXPORT_J7AM_RC_TO_HC2_VBUSP_L0_BRIDGE_BUSECC_ENABLE_CLR — Interrupt Enable Clear Register for Ij7am_rc_cbass_j7am_rc_cbass_export_j7am_rc_to_hc2_vbusp_l0_p2p_bridge_export_j7am_rc_to_hc2_vbusp_l0_bridge_busecc_pend (access R/W1TC)
  [10] IJ7AM_RC_CBASS_J7AM_RC_CBASS_EXPORT_J7AM_RC_TO_HC2_VBUSM_L1_M2M_BRIDGE_J7AM_RC_CBASS_EXPORT_J7AM_RC_TO_HC2_VBUSM_L1_M2M_BRIDGE_SRC_EDC_CTRL_BUSECC_ENABLE_CLR — Interrupt Enable Clear Register for Ij7am_rc_cbass_j7am_rc_cbass_export_j7am_rc_to_hc2_vbusm_l1_m2m_bridge_j7am_rc_cbass_export_j7am_rc_to_hc2_vbusm_l1_m2m_bridge_src_edc_ctrl_busecc_pend (access R/W1TC)
  [9] IJ7AM_RC_CBASS_J7AM_RC_CBASS_EXPORT_J7AM_HC2_TO_RC_VBUSM_L0_M2M_BRIDGE_J7AM_RC_CBASS_EXPORT_J7AM_HC2_TO_RC_VBUSM_L0_M2M_BRIDGE_SRC_EDC_CTRL_BUSECC_ENABLE_CLR — Interrupt Enable Clear Register for Ij7am_rc_cbass_j7am_rc_cbass_export_j7am_hc2_to_rc_vbusm_l0_m2m_bridge_j7am_rc_cbass_export_j7am_hc2_to_rc_vbusm_l0_m2m_bridge_src_edc_ctrl_busecc_pend (access R/W1TC)
  [8] IJ7AM_RC_CBASS_J7AM_RC_CBASS_EXPORT_J7AM_MCU_TO_RC_VBUSM_L0_M2M_BRIDGE_J7AM_RC_CBASS_EXPORT_J7AM_MCU_TO_RC_VBUSM_L0_M2M_BRIDGE_SRC_EDC_CTRL_BUSECC_ENABLE_CLR — Interrupt Enable Clear Register for Ij7am_rc_cbass_j7am_rc_cbass_export_j7am_mcu_to_rc_vbusm_l0_m2m_bridge_j7am_rc_cbass_export_j7am_mcu_to_rc_vbusm_l0_m2m_bridge_src_edc_ctrl_busecc_pend (access R/W1TC)
  [7] IJ7AM_RC_CBASS_J7AM_RC_CBASS_EXPORT_J7AM_HC2_TO_RC_VBUSM_L1_M2M_BRIDGE_J7AM_RC_CBASS_EXPORT_J7AM_HC2_TO_RC_VBUSM_L1_M2M_BRIDGE_SRC_EDC_CTRL_BUSECC_ENABLE_CLR — Interrupt Enable Clear Register for Ij7am_rc_cbass_j7am_rc_cbass_export_j7am_hc2_to_rc_vbusm_l1_m2m_bridge_j7am_rc_cbass_export_j7am_hc2_to_rc_vbusm_l1_m2m_bridge_src_edc_ctrl_busecc_pend (access R/W1TC)
  [6] IJ7AM_PULSAR0_SLV_CBASS_0_J7AM_PULSAR0_SLV_CBASS_IJ7AM_PULSAR0_MEM_CBASS_MAIN_0_CBASS_ERR_SLV_P2P_BRIDGE_IJ7AM_PULSAR0_MEM_CBASS_MAIN_0_CBASS_ERR_SLV_BRIDGE_DST_BUSECC_ENABLE_CLR — Interrupt Enable Clear Register for Ij7am_pulsar0_slv_cbass_0_j7am_pulsar0_slv_cbass_Ij7am_pulsar0_mem_cbass_main_0_cbass_err_slv_p2p_bridge_Ij7am_pulsar0_mem_cbass_main_0_cbass_err_slv_bridge_dst_busecc_pend (access R/W1TC)
  [5] IJ7AM_RC_CBASS_J7AM_RC_CBASS_INAVSS512J7AM_MAIN_0_NAV_SRAM0_M2M_BRIDGE_J7AM_RC_CBASS_INAVSS512J7AM_MAIN_0_NAV_SRAM0_M2M_BRIDGE_SRC_EDC_CTRL_BUSECC_ENABLE_CLR — Interrupt Enable Clear Register for Ij7am_rc_cbass_j7am_rc_cbass_Inavss512j7am_main_0_nav_sram0_m2m_bridge_j7am_rc_cbass_Inavss512j7am_main_0_nav_sram0_m2m_bridge_src_edc_ctrl_busecc_pend (access R/W1TC)
  [4] IRC_FW_CBASS_J7AM_RC_CBASS_MAIN_FW_CBASS_MAIN_SYSCLK0_4_CLK_EDC_CTRL_CBASS_INT_MAIN_SYSCLK0_4_BUSECC_ENABLE_CLR — Interrupt Enable Clear Register for Irc_fw_cbass_j7am_rc_cbass_main_fw_cbass_main_SYSCLK0_4_clk_edc_ctrl_cbass_int_main_SYSCLK0_4_busecc_pend (access R/W1TC)
  [3] IJ7AM_PULSAR0_SLV_CBASS_0_J7AM_PULSAR0_SLV_CBASS_IMSRAM16KX256E_MAIN_2_CFG_P2P_BRIDGE_IMSRAM16KX256E_MAIN_2_CFG_BRIDGE_BUSECC_ENABLE_CLR — Interrupt Enable Clear Register for Ij7am_pulsar0_slv_cbass_0_j7am_pulsar0_slv_cbass_Imsram16kx256e_main_2_cfg_p2p_bridge_Imsram16kx256e_main_2_cfg_bridge_busecc_pend (access R/W1TC)
  [2] IJ7AM_RC_CBASS_J7AM_RC_CBASS_EXPORT_J7AM_RC_MCU_TO_IPPHY_VBUSP_L0_M2P_BRIDGE_EXPORT_J7AM_RC_MCU_TO_IPPHY_VBUSP_L0_BRIDGE_SRC_BUSECC_ENABLE_CLR — Interrupt Enable Clear Register for Ij7am_rc_cbass_j7am_rc_cbass_export_j7am_rc_mcu_to_ipphy_vbusp_l0_m2p_bridge_export_j7am_rc_mcu_to_ipphy_vbusp_l0_bridge_src_busecc_pend (access R/W1TC)
  [1] IJ7AM_PULSAR0_SLV_CBASS_0_J7AM_PULSAR0_SLV_CBASS_SCRP_32B_CLK4_SCR_J7AM_PULSAR0_SLV_CBASS_SCRP_32B_CLK4_SCR_EDC_CTRL_BUSECC_0_ENABLE_CLR — Interrupt Enable Clear Register for Ij7am_pulsar0_slv_cbass_0_j7am_pulsar0_slv_cbass_scrp_32b_clk4_scr_j7am_pulsar0_slv_cbass_scrp_32b_clk4_scr_edc_ctrl_busecc_0_pend (access R/W1TC)
  [0] IJ7AM_RC_CBASS_J7AM_RC_CBASS_MAIN_SYSCLK0_2_CLK_EDC_CTRL_CBASS_INT_MAIN_SYSCLK0_2_BUSECC_ENABLE_CLR — Interrupt Enable Clear Register for Ij7am_rc_cbass_j7am_rc_cbass_main_SYSCLK0_2_clk_edc_ctrl_cbass_int_main_SYSCLK0_2_busecc_pend (access R/W1TC)
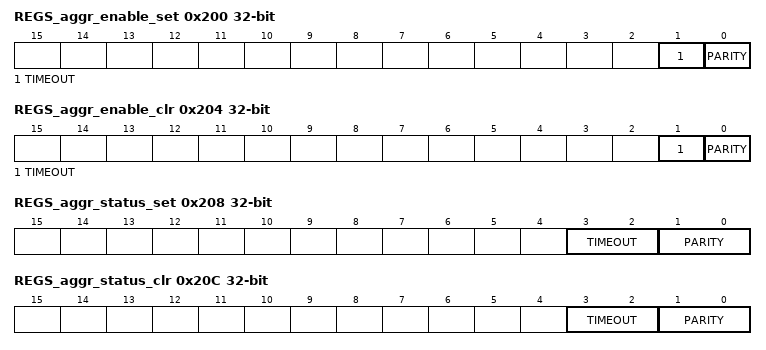
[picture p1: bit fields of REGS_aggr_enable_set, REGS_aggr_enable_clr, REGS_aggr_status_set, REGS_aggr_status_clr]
0x200 REGS_aggr_enable_set — AGGR interrupt enable set Register
  [1] TIMEOUT — interrupt enable set for svbus timeout errors (access R/W1TS)
  [0] PARITY — interrupt enable set for parity errors (access R/W1TS)
0x204 REGS_aggr_enable_clr — AGGR interrupt enable clear Register
  [1] TIMEOUT — interrupt enable clear for svbus timeout errors (access R/W1TC)
  [0] PARITY — interrupt enable clear for parity errors (access R/W1TC)
0x208 REGS_aggr_status_set — AGGR interrupt status set Register
  [3:2] TIMEOUT — interrupt status set for svbus timeout errors (access R/WI)
  [1:0] PARITY — interrupt status set for parity errors (access R/WI)
0x20C REGS_aggr_status_clr — AGGR interrupt status clear Register
  [3:2] TIMEOUT — interrupt status clear for svbus timeout errors (access R/WD)
  [1:0] PARITY — interrupt status clear for parity errors (access R/WD)
